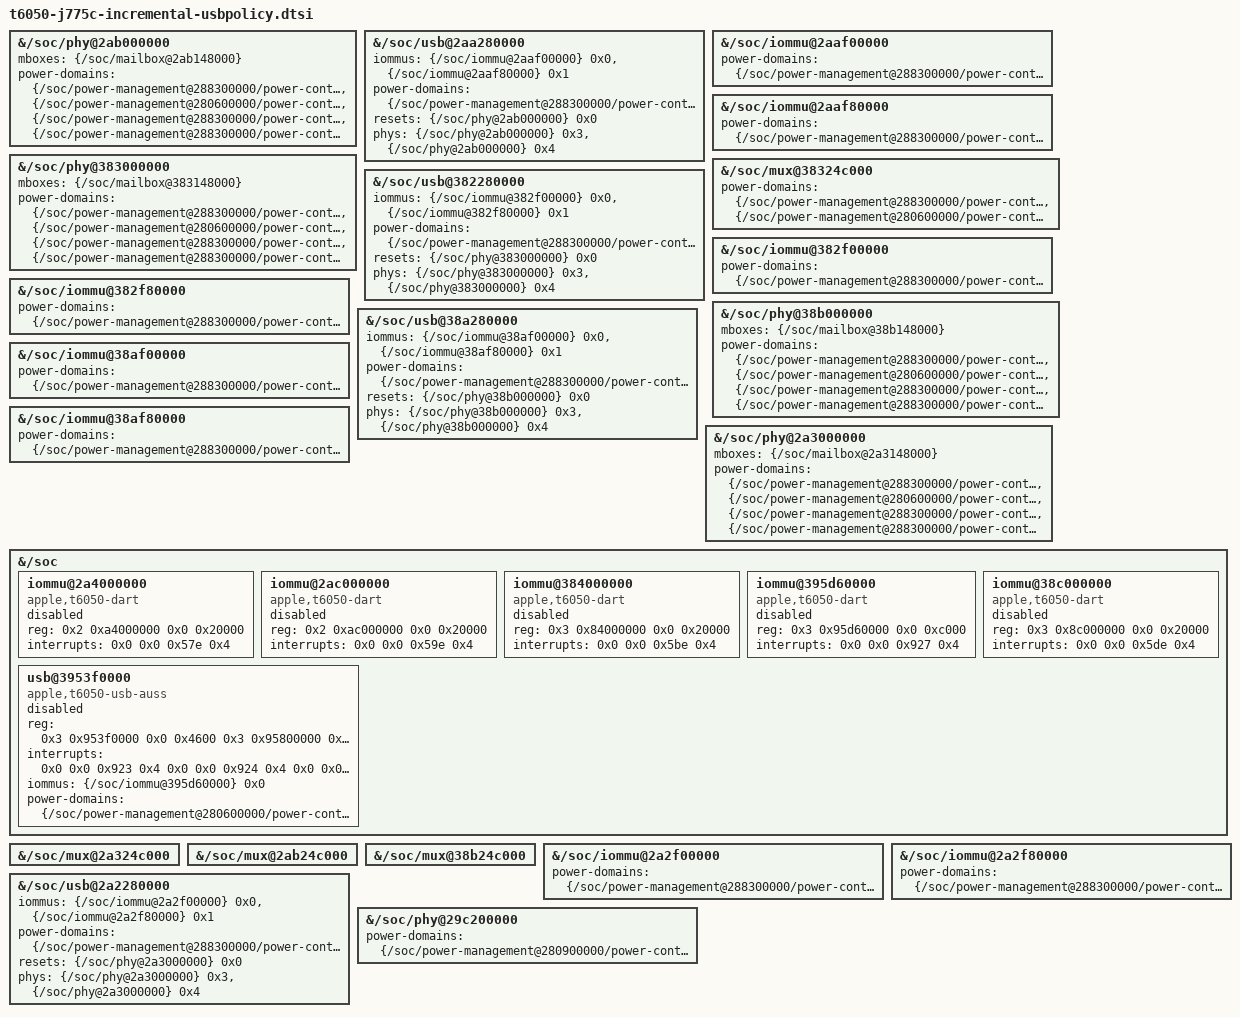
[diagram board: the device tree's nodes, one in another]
// SPDX-License-Identifier: GPL-2.0+ OR MIT
/* Property migration from Satya Benson's 86b1f365 J775c stack.
 * Retained board sources remain the baseline; this group is independently booted.
 * Copyright The Asahi Linux Contributors
 */
&{/soc/phy@2ab000000} {
	mboxes = <&{/soc/mailbox@2ab148000}>;
	power-domains = <&{/soc/power-management@288300000/power-controller@160} &{/soc/power-management@280600000/power-controller@210} &{/soc/power-management@288300000/power-controller@170} &{/soc/power-management@288300000/power-controller@168}>;
	status = "okay";
};

&{/soc/usb@2aa280000} {
	iommus = <&{/soc/iommu@2aaf00000} 0x0 &{/soc/iommu@2aaf80000} 0x1>;
	power-domains = <&{/soc/power-management@288300000/power-controller@168}>;
	resets = <&{/soc/phy@2ab000000} 0x0>;
	phys = <&{/soc/phy@2ab000000} 0x3 &{/soc/phy@2ab000000} 0x4>;
	status = "okay";
};

&{/soc/iommu@2aaf00000} {
	power-domains = <&{/soc/power-management@288300000/power-controller@168}>;
	status = "okay";
};

&{/soc/iommu@2aaf80000} {
	power-domains = <&{/soc/power-management@288300000/power-controller@168}>;
	status = "okay";
};

&{/soc/phy@383000000} {
	mboxes = <&{/soc/mailbox@383148000}>;
	power-domains = <&{/soc/power-management@288300000/power-controller@178} &{/soc/power-management@280600000/power-controller@238} &{/soc/power-management@288300000/power-controller@188} &{/soc/power-management@288300000/power-controller@180}>;
};

&{/soc/mux@38324c000} {
	power-domains = <&{/soc/power-management@288300000/power-controller@178} &{/soc/power-management@280600000/power-controller@238}>;
};

&{/soc/usb@382280000} {
	iommus = <&{/soc/iommu@382f00000} 0x0 &{/soc/iommu@382f80000} 0x1>;
	power-domains = <&{/soc/power-management@288300000/power-controller@180}>;
	resets = <&{/soc/phy@383000000} 0x0>;
	phys = <&{/soc/phy@383000000} 0x3 &{/soc/phy@383000000} 0x4>;
};

&{/soc/iommu@382f00000} {
	power-domains = <&{/soc/power-management@288300000/power-controller@180}>;
};

&{/soc/iommu@382f80000} {
	power-domains = <&{/soc/power-management@288300000/power-controller@180}>;
};

&{/soc/phy@38b000000} {
	mboxes = <&{/soc/mailbox@38b148000}>;
	power-domains = <&{/soc/power-management@288300000/power-controller@190} &{/soc/power-management@280600000/power-controller@240} &{/soc/power-management@288300000/power-controller@1a0} &{/soc/power-management@288300000/power-controller@198}>;
	status = "okay";
};

&{/soc/usb@38a280000} {
	iommus = <&{/soc/iommu@38af00000} 0x0 &{/soc/iommu@38af80000} 0x1>;
	power-domains = <&{/soc/power-management@288300000/power-controller@198}>;
	resets = <&{/soc/phy@38b000000} 0x0>;
	phys = <&{/soc/phy@38b000000} 0x3 &{/soc/phy@38b000000} 0x4>;
	status = "okay";
};

&{/soc/iommu@38af00000} {
	power-domains = <&{/soc/power-management@288300000/power-controller@198}>;
	status = "okay";
};

&{/soc/iommu@38af80000} {
	power-domains = <&{/soc/power-management@288300000/power-controller@198}>;
	status = "okay";
};

&{/soc/phy@2a3000000} {
	/delete-property/ apple,boot-link-released;
	mboxes = <&{/soc/mailbox@2a3148000}>;
	power-domains = <&{/soc/power-management@288300000/power-controller@148} &{/soc/power-management@280600000/power-controller@208} &{/soc/power-management@288300000/power-controller@158} &{/soc/power-management@288300000/power-controller@150}>;
};

&{/soc} {
	iommu@2a4000000 {
		compatible = "apple,t6050-dart", "apple,t8110-dart";
		reg = <0x2 0xa4000000 0x0 0x20000>;
		interrupts = <0x0 0x0 0x57e 0x4>;
		#iommu-cells = <0x1>;
		status = "disabled";
	};
};

&{/soc} {
	iommu@2ac000000 {
		compatible = "apple,t6050-dart", "apple,t8110-dart";
		reg = <0x2 0xac000000 0x0 0x20000>;
		interrupts = <0x0 0x0 0x59e 0x4>;
		#iommu-cells = <0x1>;
		status = "disabled";
	};
};

&{/soc} {
	iommu@384000000 {
		compatible = "apple,t6050-dart", "apple,t8110-dart";
		reg = <0x3 0x84000000 0x0 0x20000>;
		interrupts = <0x0 0x0 0x5be 0x4>;
		#iommu-cells = <0x1>;
		status = "disabled";
	};
};

&{/soc/mux@2a324c000} {
	/delete-property/ power-domain-names;
	/delete-property/ power-domains;
	status = "okay";
};

&{/soc/mux@2ab24c000} {
	/delete-property/ power-domain-names;
	/delete-property/ power-domains;
	status = "okay";
};

&{/soc/mux@38b24c000} {
	/delete-property/ power-domain-names;
	/delete-property/ power-domains;
	status = "okay";
};

&{/soc/iommu@2a2f00000} {
	/delete-property/ apple,dma-range;
	power-domains = <&{/soc/power-management@288300000/power-controller@150}>;
	status = "okay";
};

&{/soc/iommu@2a2f80000} {
	/delete-property/ apple,dma-range;
	power-domains = <&{/soc/power-management@288300000/power-controller@150}>;
	status = "okay";
};

&{/soc/usb@2a2280000} {
	iommus = <&{/soc/iommu@2a2f00000} 0x0 &{/soc/iommu@2a2f80000} 0x1>;
	power-domains = <&{/soc/power-management@288300000/power-controller@150}>;
	status = "okay";
	resets = <&{/soc/phy@2a3000000} 0x0>;
	phys = <&{/soc/phy@2a3000000} 0x3 &{/soc/phy@2a3000000} 0x4>;
};

&{/soc} {
	iommu@395d60000 {
		compatible = "apple,t6050-dart", "apple,t8110-dart";
		reg = <0x3 0x95d60000 0x0 0xc000>;
		interrupts = <0x0 0x0 0x927 0x4>;
		#iommu-cells = <0x1>;
		status = "disabled";
	};
};

&{/soc} {
	usb@3953f0000 {
		compatible = "apple,t6050-usb-auss";
		reg = <0x3 0x953f0000 0x0 0x4600 0x3 0x95800000 0x0 0x4000 0x3 0x95803c00 0x0 0x4000 0x3 0x95804000 0x0 0x4000 0x3 0x94000000 0x0 0x8000 0x3 0x95d80000 0x0 0x4000 0x3 0x95d84000 0x0 0x4000 0x3 0x95e40000 0x0 0x4000 0x3 0x95e3c000 0x0 0x4000 0x3 0x95d98000 0x0 0x4000>;
		interrupts = <0x0 0x0 0x923 0x4 0x0 0x0 0x924 0x4 0x0 0x0 0x925 0x4 0x0 0x0 0x926 0x4>;
		iommus = <&{/soc/iommu@395d60000} 0x0>;
		power-domains = <&{/soc/power-management@280600000/power-controller@248}>;
		status = "disabled";
	};
};

&{/soc} {
	iommu@38c000000 {
		compatible = "apple,t6050-dart", "apple,t8110-dart";
		reg = <0x3 0x8c000000 0x0 0x20000>;
		interrupts = <0x0 0x0 0x5de 0x4>;
		#iommu-cells = <0x1>;
		status = "disabled";
	};
};

&{/soc/phy@29c200000} {
	power-domains = <&{/soc/power-management@280900000/power-controller@3f8}>;
};
